# STM32C011D6Y6 register map
File version: 1.0
Registers are 32-bit, access not given, reset 0x0 unless marked. A register's access mark holds for its fields unless they carry their own. Offsets are from the block's base; [hi:lo] are bit positions; {n}, {i} and the like mark numbered series; 'fields as' and 'values as' point back to an identical list.

## SPI1
Base 0x40013000
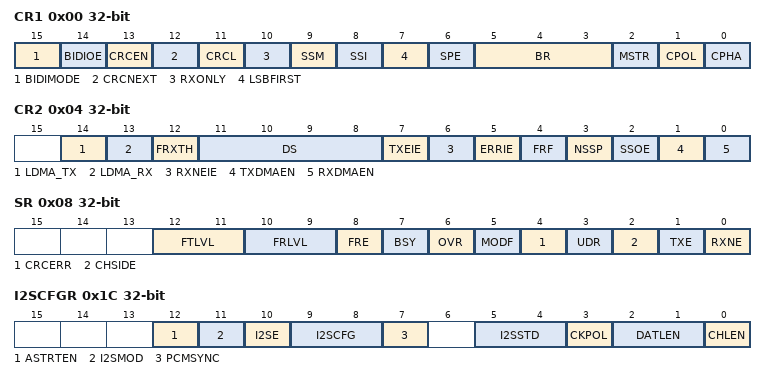
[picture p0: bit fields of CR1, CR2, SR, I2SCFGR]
0x00 CR1
  [15] BIDIMODE, [14] BIDIOE, [13] CRCEN, [12] CRCNEXT, [11] CRCL, [10] RXONLY, [9] SSM, [8] SSI, [7] LSBFIRST, [6] SPE, [5:3] BR, [2] MSTR, [1] CPOL, [0] CPHA
0x04 CR2
  [14] LDMA_TX, [13] LDMA_RX, [12] FRXTH, [11:8] DS, [7] TXEIE, [6] RXNEIE, [5] ERRIE, [4] FRF, [3] NSSP, [2] SSOE, [1] TXDMAEN, [0] RXDMAEN
0x08 SR
  [12:11] FTLVL, [10:9] FRLVL, [8] FRE, [7] BSY, [6] OVR, [5] MODF, [4] CRCERR, [3] UDR, [2] CHSIDE, [1] TXE, [0] RXNE
0x0C DR
  [15:0] DR
0x10 CRCPR
  [15:0] CRCPOLY
0x14 RXCRCR
  [15:0] RXCRC
0x18 TXCRCR
  [15:0] TXCRC
0x1C I2SCFGR
  [12] ASTRTEN, [11] I2SMOD, [10] I2SE, [9:8] I2SCFG, [7] PCMSYNC, [5:4] I2SSTD, [3] CKPOL, [2:1] DATLEN, [0] CHLEN
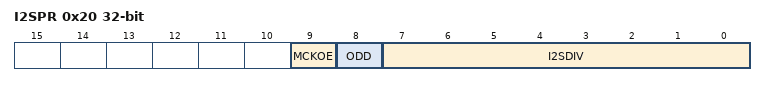
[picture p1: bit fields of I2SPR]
0x20 I2SPR
  [9] MCKOE, [8] ODD, [7:0] I2SDIV

## TIM16
Base 0x40014400
Same registers: TIM17 0x40014800
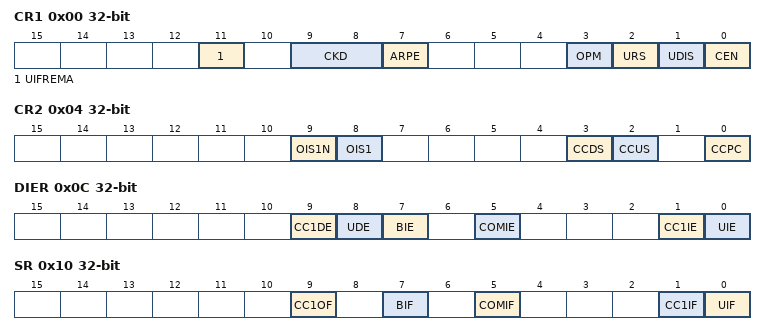
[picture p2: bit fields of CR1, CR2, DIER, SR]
0x00 CR1
  [11] UIFREMA, [9:8] CKD, [7] ARPE, [3] OPM, [2] URS, [1] UDIS, [0] CEN
0x04 CR2
  [9] OIS1N, [8] OIS1, [3] CCDS, [2] CCUS, [0] CCPC
0x0C DIER
  [9] CC1DE, [8] UDE, [7] BIE, [5] COMIE, [1] CC1IE, [0] UIE
0x10 SR
  [9] CC1OF, [7] BIF, [5] COMIF, [1] CC1IF, [0] UIF
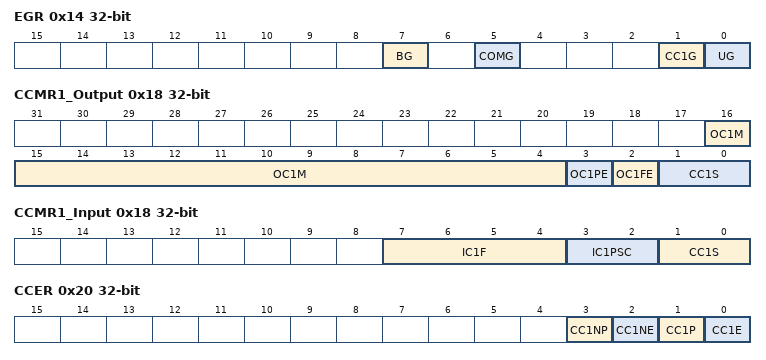
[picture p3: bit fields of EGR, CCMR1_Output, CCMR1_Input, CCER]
0x14 EGR
  [7] BG, [5] COMG, [1] CC1G, [0] UG
0x18 CCMR1_Output
  [16:4] OC1M, [3] OC1PE, [2] OC1FE, [1:0] CC1S
0x18 CCMR1_Input
  [7:4] IC1F, [3:2] IC1PSC, [1:0] CC1S
0x20 CCER
  [3] CC1NP, [2] CC1NE, [1] CC1P, [0] CC1E
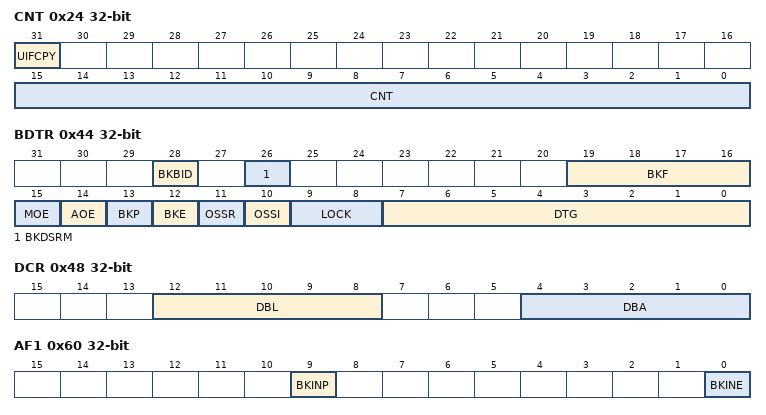
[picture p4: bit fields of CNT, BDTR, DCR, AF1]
0x24 CNT
  [31] UIFCPY, [15:0] CNT
0x28 PSC
  [15:0] PSC
0x2C ARR
  [15:0] ARR
0x30 RCR
  [7:0] REP
0x34 CCR1
  [15:0] CCR1
0x44 BDTR
  [28] BKBID, [26] BKDSRM, [19:16] BKF, [15] MOE, [14] AOE, [13] BKP, [12] BKE, [11] OSSR, [10] OSSI, [9:8] LOCK, [7:0] DTG
0x48 DCR
  [12:8] DBL, [4:0] DBA
0x4C DMAR
  [15:0] DMAB
0x60 AF1
  [9] BKINP, [0] BKINE
0x68 TISEL
  [3:0] TI1SEL

## DBG
Base 0x40015800
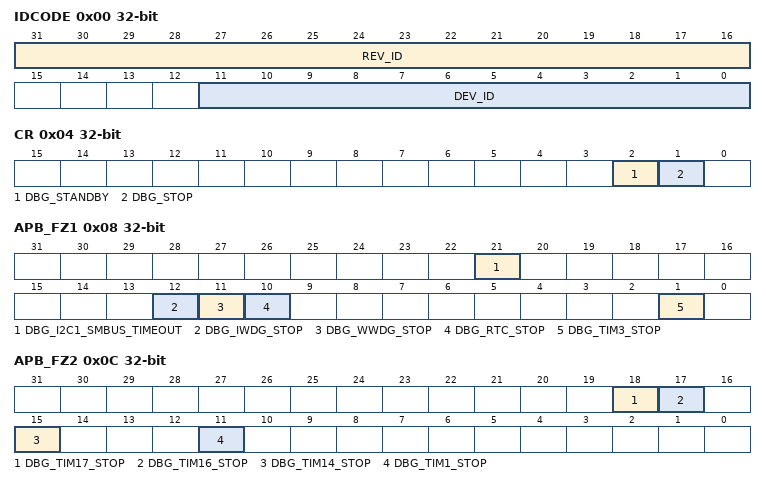
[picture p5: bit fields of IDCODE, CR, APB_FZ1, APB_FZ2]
0x00 IDCODE
  [31:16] REV_ID, [11:0] DEV_ID
0x04 CR
  [2] DBG_STANDBY, [1] DBG_STOP
0x08 APB_FZ1
  [21] DBG_I2C1_SMBUS_TIMEOUT, [12] DBG_IWDG_STOP, [11] DBG_WWDG_STOP, [10] DBG_RTC_STOP, [1] DBG_TIM3_STOP
0x0C APB_FZ2
  [18] DBG_TIM17_STOP, [17] DBG_TIM16_STOP, [15] DBG_TIM14_STOP, [11] DBG_TIM1_STOP

## DMA1
Base 0x40020000
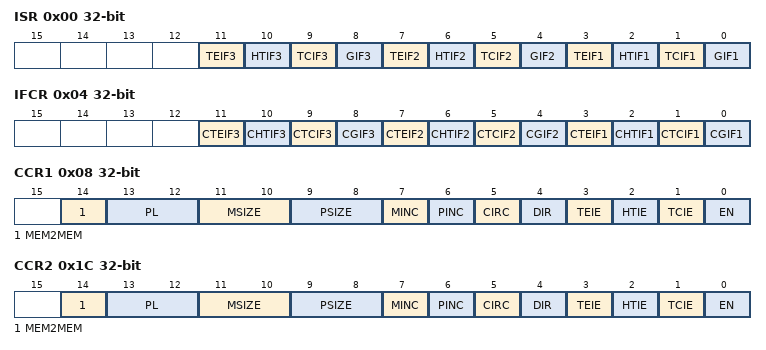
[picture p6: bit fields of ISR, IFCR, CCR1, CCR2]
0x00 ISR
  [11] TEIF3, [10] HTIF3, [9] TCIF3, [8] GIF3, [7] TEIF2, [6] HTIF2, [5] TCIF2, [4] GIF2, [3] TEIF1, [2] HTIF1, [1] TCIF1, [0] GIF1
0x04 IFCR
  [11] CTEIF3, [10] CHTIF3, [9] CTCIF3, [8] CGIF3, [7] CTEIF2, [6] CHTIF2, [5] CTCIF2, [4] CGIF2, [3] CTEIF1, [2] CHTIF1, [1] CTCIF1, [0] CGIF1
0x08 CCR1
  [14] MEM2MEM, [13:12] PL, [11:10] MSIZE, [9:8] PSIZE, [7] MINC, [6] PINC, [5] CIRC, [4] DIR, [3] TEIE, [2] HTIE, [1] TCIE, [0] EN
0x0C CNDTR1
  [15:0] NDTR
0x10 CPAR1
  [31:0] PA
{0x0+0x14*i} CMAR{i} (i=1..3)
  [31:0] MA
0x1C CCR2
  fields as CCR1
0x20 CNDTR2
  [15:0] NDTR
0x24 CPAR2
  [31:0] PA
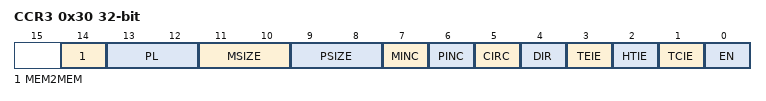
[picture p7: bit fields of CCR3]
0x30 CCR3
  fields as CCR1
0x34 CNDTR3
  [15:0] NDTR
0x38 CPAR3
  [31:0] PA

## DMAMUX
Base 0x40020800
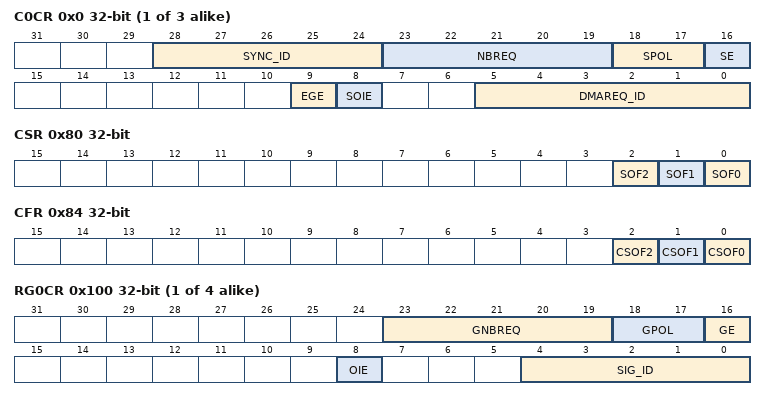
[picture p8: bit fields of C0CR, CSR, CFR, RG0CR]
{0x0+4i} C{i}CR (i=0..2)
  [28:24] SYNC_ID, [23:19] NBREQ, [18:17] SPOL, [16] SE, [9] EGE, [8] SOIE, [5:0] DMAREQ_ID
0x80 CSR
  [2] SOF2, [1] SOF1, [0] SOF0
0x84 CFR
  [2] CSOF2, [1] CSOF1, [0] CSOF0
{0x100+4i} RG{i}CR (i=0..3)
  [23:19] GNBREQ, [18:17] GPOL, [16] GE, [8] OIE, [4:0] SIG_ID
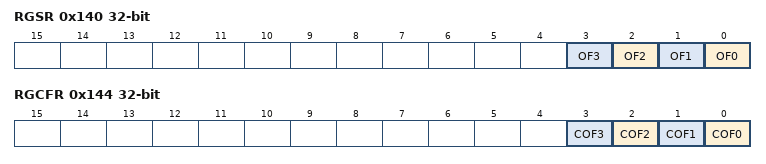
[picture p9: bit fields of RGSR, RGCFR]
0x140 RGSR
  [n] OF{n} (n=0..3)
0x144 RGCFR
  [n] COF{n} (n=0..3)

## RCC
Base 0x40021000
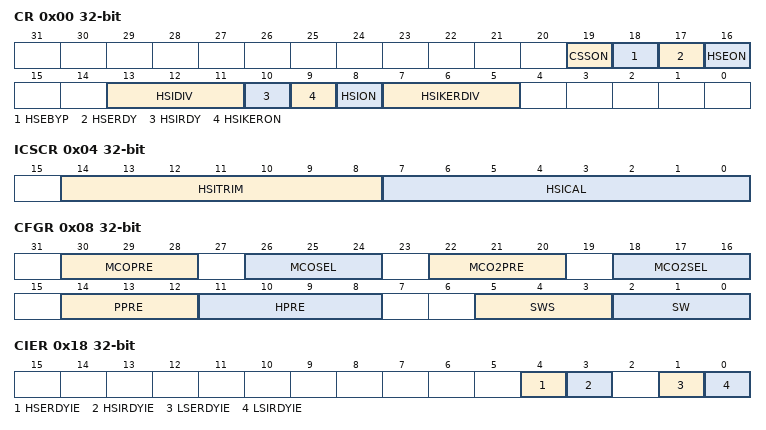
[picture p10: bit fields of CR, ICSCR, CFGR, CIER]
0x00 CR
  [19] CSSON, [18] HSEBYP, [17] HSERDY, [16] HSEON, [13:11] HSIDIV, [10] HSIRDY, [9] HSIKERON, [8] HSION, [7:5] HSIKERDIV
0x04 ICSCR
  [14:8] HSITRIM, [7:0] HSICAL
0x08 CFGR
  [30:28] MCOPRE, [26:24] MCOSEL, [22:20] MCO2PRE, [18:16] MCO2SEL, [14:12] PPRE, [11:8] HPRE, [5:3] SWS, [2:0] SW
0x18 CIER
  [4] HSERDYIE, [3] HSIRDYIE, [1] LSERDYIE, [0] LSIRDYIE
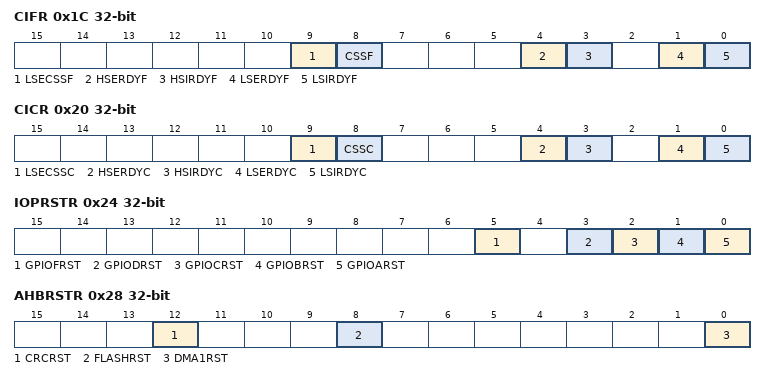
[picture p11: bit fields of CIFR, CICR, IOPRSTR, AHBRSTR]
0x1C CIFR
  [9] LSECSSF, [8] CSSF, [4] HSERDYF, [3] HSIRDYF, [1] LSERDYF, [0] LSIRDYF
0x20 CICR
  [9] LSECSSC, [8] CSSC, [4] HSERDYC, [3] HSIRDYC, [1] LSERDYC, [0] LSIRDYC
0x24 IOPRSTR
  [5] GPIOFRST, [3] GPIODRST, [2] GPIOCRST, [1] GPIOBRST, [0] GPIOARST
0x28 AHBRSTR
  [12] CRCRST, [8] FLASHRST, [0] DMA1RST
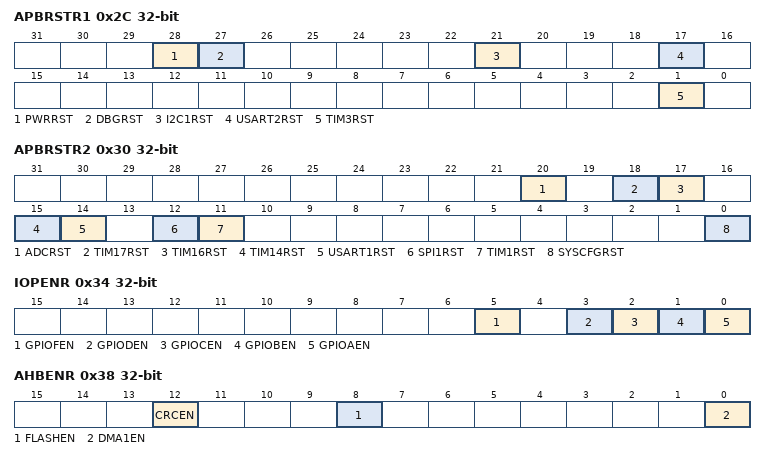
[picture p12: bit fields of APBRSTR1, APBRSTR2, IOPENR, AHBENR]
0x2C APBRSTR1
  [28] PWRRST, [27] DBGRST, [21] I2C1RST, [17] USART2RST, [1] TIM3RST
0x30 APBRSTR2
  [20] ADCRST, [18] TIM17RST, [17] TIM16RST, [15] TIM14RST, [14] USART1RST, [12] SPI1RST, [11] TIM1RST, [0] SYSCFGRST
0x34 IOPENR
  [5] GPIOFEN, [3] GPIODEN, [2] GPIOCEN, [1] GPIOBEN, [0] GPIOAEN
0x38 AHBENR
  [12] CRCEN, [8] FLASHEN, [0] DMA1EN
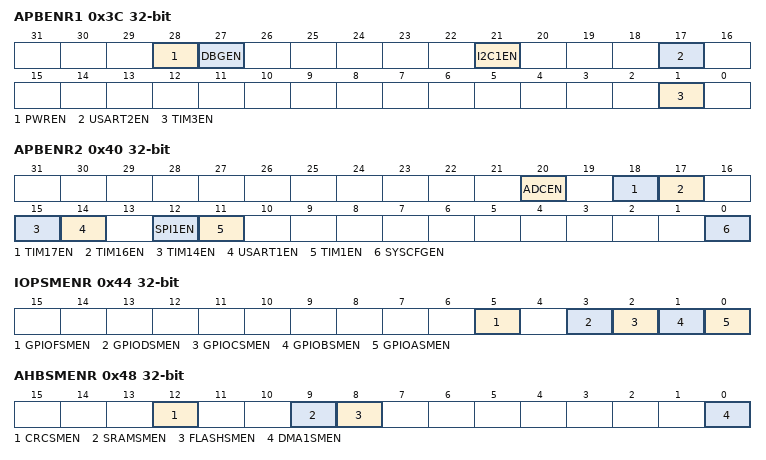
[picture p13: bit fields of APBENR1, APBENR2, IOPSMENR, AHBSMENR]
0x3C APBENR1
  [28] PWREN, [27] DBGEN, [21] I2C1EN, [17] USART2EN, [1] TIM3EN
0x40 APBENR2
  [20] ADCEN, [18] TIM17EN, [17] TIM16EN, [15] TIM14EN, [14] USART1EN, [12] SPI1EN, [11] TIM1EN, [0] SYSCFGEN
0x44 IOPSMENR
  [5] GPIOFSMEN, [3] GPIODSMEN, [2] GPIOCSMEN, [1] GPIOBSMEN, [0] GPIOASMEN
0x48 AHBSMENR
  [12] CRCSMEN, [9] SRAMSMEN, [8] FLASHSMEN, [0] DMA1SMEN
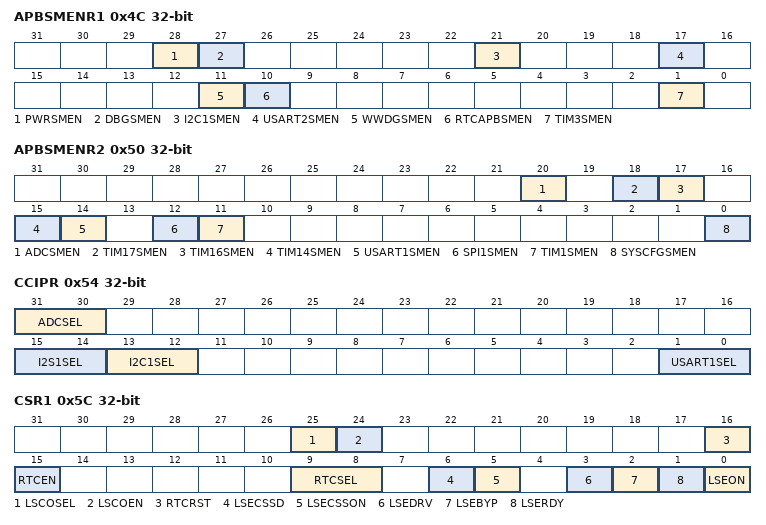
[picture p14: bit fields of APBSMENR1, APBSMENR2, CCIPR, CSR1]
0x4C APBSMENR1
  [28] PWRSMEN, [27] DBGSMEN, [21] I2C1SMEN, [17] USART2SMEN, [11] WWDGSMEN, [10] RTCAPBSMEN, [1] TIM3SMEN
0x50 APBSMENR2
  [20] ADCSMEN, [18] TIM17SMEN, [17] TIM16SMEN, [15] TIM14SMEN, [14] USART1SMEN, [12] SPI1SMEN, [11] TIM1SMEN, [0] SYSCFGSMEN
0x54 CCIPR
  [31:30] ADCSEL, [15:14] I2S1SEL, [13:12] I2C1SEL, [1:0] USART1SEL
0x5C CSR1
  [25] LSCOSEL, [24] LSCOEN, [16] RTCRST, [15] RTCEN, [9:8] RTCSEL, [6] LSECSSD, [5] LSECSSON, [3] LSEDRV, [2] LSEBYP, [1] LSERDY, [0] LSEON
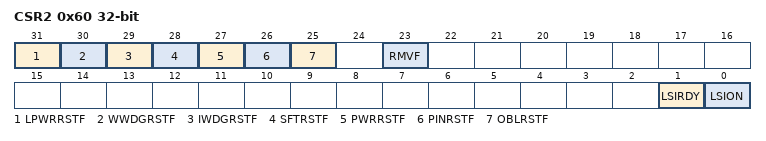
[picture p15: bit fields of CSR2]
0x60 CSR2
  [31] LPWRRSTF, [30] WWDGRSTF, [29] IWDGRSTF, [28] SFTRSTF, [27] PWRRSTF, [26] PINRSTF, [25] OBLRSTF, [23] RMVF, [1] LSIRDY, [0] LSION

## EXTI
Base 0x40021800
0x00 RTSR1
  [15:0] RT
0x04 FTSR1
  [15:0] FT
0x08 SWIER1
  [15:0] SWI
0x0C RPR1
  [15:0] RPIF
0x10 FPR1
  [15:0] FPIF
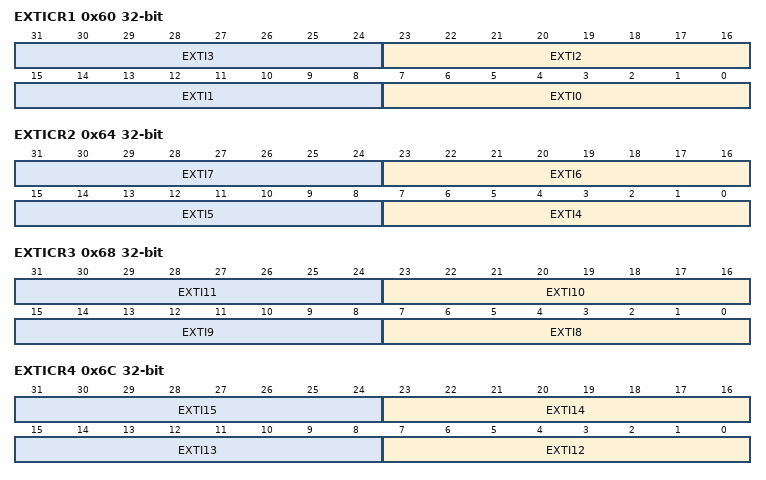
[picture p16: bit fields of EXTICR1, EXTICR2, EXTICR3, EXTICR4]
0x60 EXTICR1
  [8n+7:8n] EXTI{n} (n=0..3)
0x64 EXTICR2
  [8n-25:8n-32] EXTI{n} (n=4..7)
0x68 EXTICR3
  [8n-57:8n-64] EXTI{n} (n=8..11)
0x6C EXTICR4
  [8n-89:8n-96] EXTI{n} (n=12..15)
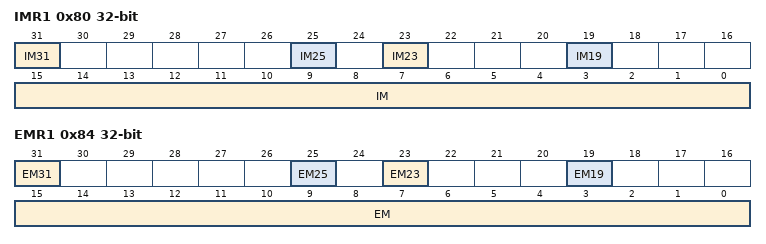
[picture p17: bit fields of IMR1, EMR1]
0x80 IMR1
  [31] IM31, [25] IM25, [23] IM23, [19] IM19, [15:0] IM
0x84 EMR1
  [31] EM31, [25] EM25, [23] EM23, [19] EM19, [15:0] EM

## FLASH
Base 0x40022000
0x00 ACR
  [18] DBG_SWEN, [16] EMPTY, [11] ICRST, [9] ICEN, [8] PRFTEN, [2:0] LATENCY
0x08 KEYR
0x0C OPTKEYR
  [31:0] OPTKEY
0x10 SR
  [18] CFGBSY, [16] BSY1, [15] OPTVERR, [14] RDERR, [9] FASTERR, [8] MISERR, [7] PGSERR, [6] SIZERR, [5] PGAERR, [4] WRPERR, [3] PROGERR, [1] OPERR, [0] EOP
0x14 CR
  [31] LOCK, [30] OPTLOCK, [28] SEC_PROT, [27] OBL_LAUNCH, [26] RDERRIE, [25] ERRIE, [24] EOPIE, [18] FSTPG, [17] OPTSTRT, [16] STRT, [6:3] PNB, [2] MER1, [1] PER, [0] PG
0x20 OPTR
  [29] IRHEN, [28:27] NRST_MODE, [26] nBOOT0, [25] nBOOT1, [24] nBOOT_SEL, [23] SECURE_MUXING_EN, [22] RAM_PARITY_CHECK, [21] HSE_NOT_REMAPPED, [19] WWDG_SW, [18] IWDG_STBY, [17] IWDG_STOP, [16] IWDG_SW, [15] nRST_SHDW, [14] nRST_STDBY, [13] nRST_STOP, [12:11] BORF_LEV, [10:9] BORR_LEV, [8] BOR_EN, [7:0] RDP
0x24 PCROP1ASR
  [5:0] PCROP1A_STRT
0x28 PCROP1AER
  [31] PCROP_RDP, [5:0] PCROP1A_END
0x2C WRP1AR
  [19:16] WRP1A_END, [3:0] WRP1A_STRT
0x30 WRP1BR
  [19:16] WRP1B_END, [3:0] WRP1B_STRT
0x34 PCROP1BSR
  [5:0] PCROP1B_STRT
0x38 PCROP1BER
  [5:0] PCROP1B_END
0x80 SECR
  [16] BOOT_LOCK, [4:0] SEC_SIZE

## CRC
Base 0x40023000
0x00 DR
0x04 IDR
0x08 CR
  [7] REV_OUT, [6:5] REV_IN, [4:3] POLYSIZE, [0] RESET
0x10 INIT
  [31:0] CRC_INIT
0x14 POL

## GPIOA
Base 0x50000000
Same registers: GPIOB 0x50000400, GPIOC 0x50000800, GPIOD 0x50000C00, GPIOF 0x50001400
0x00 MODER
  [2n+1:2n] MODE{n} (n=0..15)
0x04 OTYPER
  [n] OT{n} (n=0..15)
0x08 OSPEEDR
  [2n+1:2n] OSPEED{n} (n=0..15)
0x0C PUPDR
  [2n+1:2n] PUPD{n} (n=0..15)
0x10 IDR
  [n] ID{n} (n=0..15)
0x14 ODR
  [n] OD{n} (n=0..15)
0x18 BSRR
  [n+16] BR{n} (n=0..15), [n] BS{n} (n=0..15)
0x1C LCKR
  [16] LCKK, [n] LCK{n} (n=0..15)
0x20 AFRL
  [4n+3:4n] AFSEL{n} (n=0..7)
0x24 AFRH
  [4n-29:4n-32] AFSEL{n} (n=8..15)
0x28 BRR
  [n] BR{n} (n=0..15)
